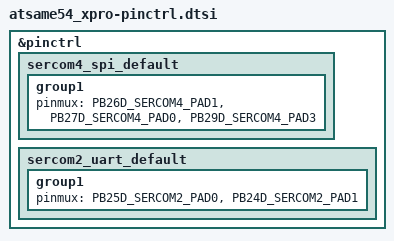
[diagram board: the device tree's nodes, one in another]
/*
 * Copyright (c) 2022, Gerson Fernando Budke <nandojve@gmail.com>
 * SPDX-License-Identifier: Apache-2.0
 */

#include <dt-bindings/pinctrl/same54p-pinctrl.h>

&pinctrl {
	sercom4_spi_default: sercom4_spi_default {
		group1 {
			pinmux = <PB26D_SERCOM4_PAD1>,
				 <PB27D_SERCOM4_PAD0>,
				 <PB29D_SERCOM4_PAD3>;
		};
	};

	sercom2_uart_default: sercom2_uart_default {
		group1 {
			pinmux = <PB25D_SERCOM2_PAD0>,
				 <PB24D_SERCOM2_PAD1>;
		};
	};
};
